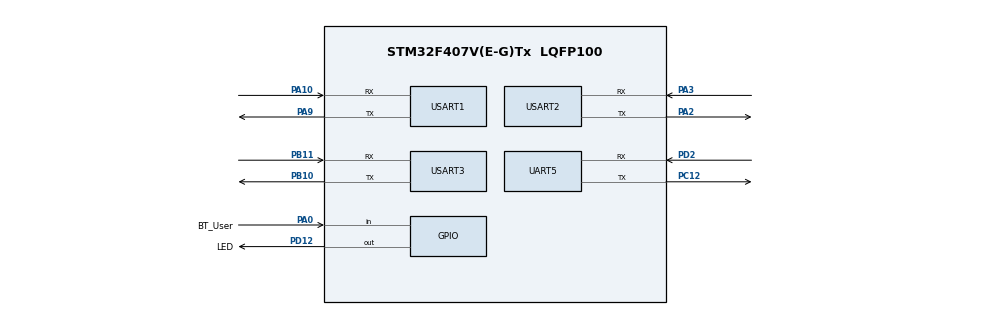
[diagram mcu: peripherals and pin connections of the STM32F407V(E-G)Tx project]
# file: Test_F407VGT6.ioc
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Mcu.Family=STM32F4
Mcu.Name=STM32F407V(E-G)Tx
Mcu.Package=LQFP100
NVIC.PriorityGroup=NVIC_PRIORITYGROUP_4
NVIC.UART5_IRQn=true\:0\:0\:false\:false\:true\:true\:true\:true
NVIC.USART1_IRQn=true\:0\:0\:false\:false\:true\:true\:true\:true
NVIC.USART2_IRQn=true\:0\:0\:false\:false\:true\:true\:true\:true
NVIC.USART3_IRQn=true\:0\:0\:false\:false\:true\:true\:true\:true
PA0-WKUP.GPIO_Label=BT_User
PA0-WKUP.Signal=GPIO_Input
PA10.Mode=Asynchronous
PA10.Signal=USART1_RX
PA2.Mode=Asynchronous
PA2.Signal=USART2_TX
PA3.Mode=Asynchronous
PA3.Signal=USART2_RX
PA9.Mode=Asynchronous
PA9.Signal=USART1_TX
PB10.Mode=Asynchronous
PB10.Signal=USART3_TX
PB11.Mode=Asynchronous
PB11.Signal=USART3_RX
PC12.Mode=Asynchronous
PC12.Signal=UART5_TX
PD12.GPIO_Label=LED
PD12.Signal=GPIO_Output
PD2.Mode=Asynchronous
PD2.Signal=UART5_RX
ProjectManager.HeapSize=0x200
ProjectManager.StackSize=0x400
ProjectManager.TargetToolchain=STM32CubeIDE
RCC.AHBFreq_Value=16000000
RCC.APB1Freq_Value=16000000
RCC.APB2Freq_Value=16000000
RCC.CortexFreq_Value=16000000
RCC.HSE_VALUE=25000000
RCC.HSI_VALUE=16000000
RCC.LSE_VALUE=32768
RCC.SYSCLKFreq_VALUE=16000000
RCC.VCOOutputFreq_Value=192000000
UART5.VirtualMode=Asynchronous
USART1.VirtualMode=VM_ASYNC
USART2.VirtualMode=VM_ASYNC
USART3.VirtualMode=VM_ASYNC
board=custom

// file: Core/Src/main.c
/* USER CODE BEGIN Header */
/**
  ******************************************************************************
  * @file           : main.c
  * @brief          : Main program body
  ******************************************************************************
  * @attention
  *
  * Copyright (c) 2024 STMicroelectronics.
  * All rights reserved.
  *
  * This software is licensed under terms that can be found in the LICENSE file
  * in the root directory of this software component.
  * If no LICENSE file comes with this software, it is provided AS-IS.
  *
  ******************************************************************************
  */
/* USER CODE END Header */
#include "main.h"
#include "usart.h"
#include "gpio.h"

void SystemClock_Config(void);

int main(void)
{

  /* MCU Configuration--------------------------------------------------------*/

  /* Reset of all peripherals, Initializes the Flash interface and the Systick. */
  LL_APB2_GRP1_EnableClock(LL_APB2_GRP1_PERIPH_SYSCFG);
  LL_APB1_GRP1_EnableClock(LL_APB1_GRP1_PERIPH_PWR);

  /* System interrupt init*/
  NVIC_SetPriorityGrouping(NVIC_PRIORITYGROUP_4);

  /* SysTick_IRQn interrupt configuration */
  NVIC_SetPriority(SysTick_IRQn, NVIC_EncodePriority(NVIC_GetPriorityGrouping(),15, 0));

  /* Configure the system clock */
  SystemClock_Config();

  /* USER CODE BEGIN SysInit */
#if 0
  /* USER CODE END SysInit */

  /* Initialize all configured peripherals */
  MX_GPIO_Init();
  MX_UART5_Init();
  MX_USART1_UART_Init();
  MX_USART2_UART_Init();
  MX_USART3_UART_Init();
  /* USER CODE BEGIN 2 */
#endif
  //LL_GPIO_SetOutputPin(LED_GPIO_Port, LED_Pin);
  alt_main();

  /* USER CODE END 2 */

  /* Infinite loop */
  while (1)
  {

  }
}

void SystemClock_Config(void)
{
  LL_FLASH_SetLatency(LL_FLASH_LATENCY_0);
  while(LL_FLASH_GetLatency()!= LL_FLASH_LATENCY_0)
  {
  }
  LL_PWR_SetRegulVoltageScaling(LL_PWR_REGU_VOLTAGE_SCALE1);
  LL_RCC_HSI_SetCalibTrimming(16);
  LL_RCC_HSI_Enable();

   /* Wait till HSI is ready */
  while(LL_RCC_HSI_IsReady() != 1)
  {

  }
  LL_RCC_SetAHBPrescaler(LL_RCC_SYSCLK_DIV_1);
  LL_RCC_SetAPB1Prescaler(LL_RCC_APB1_DIV_1);
  LL_RCC_SetAPB2Prescaler(LL_RCC_APB2_DIV_1);
  LL_RCC_SetSysClkSource(LL_RCC_SYS_CLKSOURCE_HSI);

   /* Wait till System clock is ready */
  while(LL_RCC_GetSysClkSource() != LL_RCC_SYS_CLKSOURCE_STATUS_HSI)
  {

  }
  LL_Init1msTick(16000000);
  LL_SetSystemCoreClock(16000000);
}

void Error_Handler(void)
{
  __disable_irq();
  while (1)
  {
  }
}
